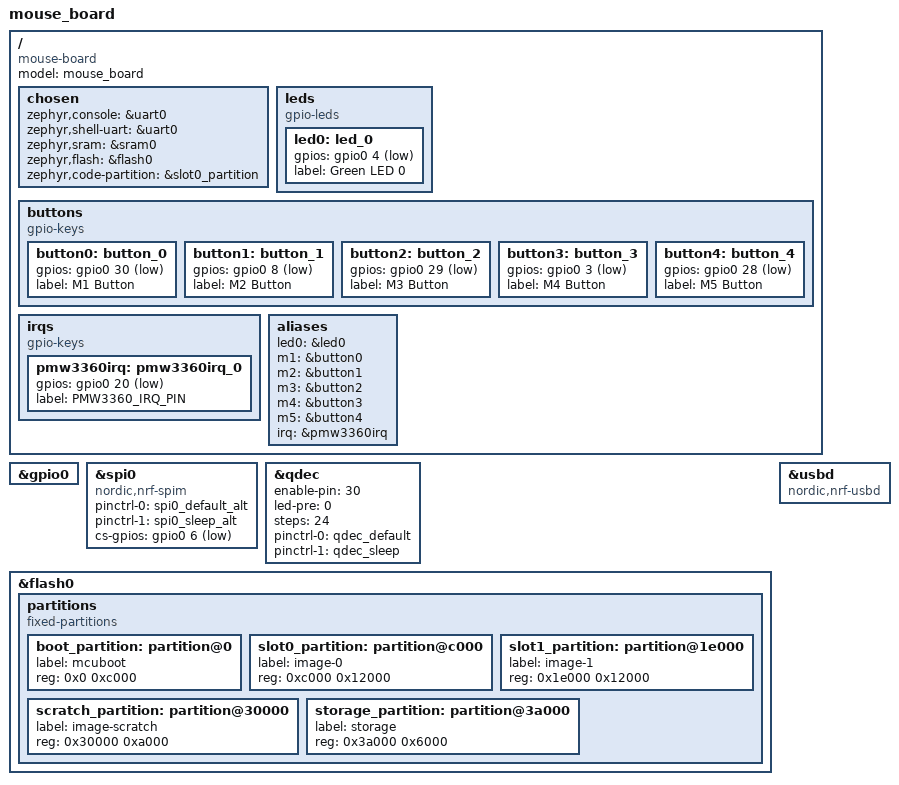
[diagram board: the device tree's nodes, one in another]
// Copyright (c) 2022 Nordic Semiconductor ASA
// SPDX-License-Identifier: Apache-2.0

/dts-v1/;
#include <nordic/nrf52820_qdaa.dtsi>
#include "mouse_board-pinctrl.dtsi"

/ {
	model = "mouse_board";
	compatible = "mouse-board";

	chosen {
		zephyr,console = &uart0;
		zephyr,shell-uart = &uart0;
		zephyr,sram = &sram0;
		zephyr,flash = &flash0;
		zephyr,code-partition = &slot0_partition;
	};

	leds {
		compatible = "gpio-leds";
		led0: led_0 {
			gpios = <&gpio0 4 GPIO_ACTIVE_LOW>;
			label = "Green LED 0";
		};
	};

	buttons {
		compatible = "gpio-keys";
		button0: button_0 {
			gpios = < &gpio0 30 (GPIO_PULL_UP | GPIO_ACTIVE_LOW)>;
			label = "M1 Button";
		};
		button1: button_1 {
			gpios = < &gpio0 8 (GPIO_PULL_UP | GPIO_ACTIVE_LOW)>;
			label = "M2 Button";
		};
		button2: button_2 {
			gpios = < &gpio0 29 (GPIO_PULL_UP | GPIO_ACTIVE_LOW)>;
			label = "M3 Button";
		};
		button3: button_3 {
			gpios = < &gpio0 3 (GPIO_PULL_UP | GPIO_ACTIVE_LOW)>;
			label = "M4 Button";
		};
		button4: button_4 {
			gpios = < &gpio0 28 (GPIO_PULL_UP | GPIO_ACTIVE_LOW)>;
			label = "M5 Button";
		};
	};
	irqs {
        compatible = "gpio-keys";
        pmw3360irq: pmw3360irq_0 {
            gpios = <&gpio0 20 (GPIO_ACTIVE_LOW | GPIO_PULL_UP)>;
            label = "PMW3360_IRQ_PIN";
        };
    };

	/* These aliases are provided for compatibility with samples */
	aliases {
		led0 = &led0;
		m1 = &button0;
		m2 = &button1;
		m3 = &button2;
		m4 = &button3;
		m5 = &button4;

        irq = &pmw3360irq;
	};
};

&gpio0 {
	status = "okay";
};

&spi0 {
	compatible = "nordic,nrf-spim";
	status = "okay";
	pinctrl-0 = <&spi0_default_alt>;
	pinctrl-1 = <&spi0_sleep_alt>;
	pinctrl-names = "default", "sleep";
	cs-gpios = <&gpio0 6 GPIO_ACTIVE_LOW>;
};


&qdec {
	status = "okay";
	enable-pin = <30>;
	led-pre = <0>;
	steps = <24>;
	pinctrl-0 = <&qdec_default>;
	pinctrl-1 = <&qdec_sleep>;
	pinctrl-names = "default", "sleep";
};

&flash0 {
	partitions {
		compatible = "fixed-partitions";
		#address-cells = <1>;
		#size-cells = <1>;

		boot_partition: partition@0 {
			label = "mcuboot";
			reg = <0x0 0xc000>;
		};
		slot0_partition: partition@c000 {
			label = "image-0";
			reg = <0xc000 0x12000>;
		};
		slot1_partition: partition@1e000 {
			label = "image-1";
			reg = <0x1e000 0x12000>;
		};
		scratch_partition: partition@30000 {
			label = "image-scratch";
			reg = <0x30000 0xa000>;
		};
		storage_partition: partition@3a000 {
			label = "storage";
			reg = <0x3a000 0x6000>;
		};
	};
};

zephyr_udc0: &usbd {
	compatible = "nordic,nrf-usbd";
	status = "okay";
};
